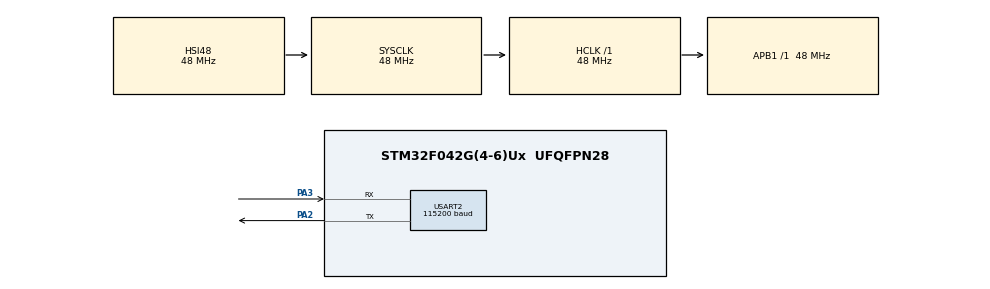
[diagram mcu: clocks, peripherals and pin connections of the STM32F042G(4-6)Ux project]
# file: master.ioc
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Mcu.Family=STM32F0
Mcu.Name=STM32F042G(4-6)Ux
Mcu.Package=UFQFPN28
NVIC.USART2_IRQn=true\:0\:0\:false\:false\:true\:true\:true
PA13.Mode=Serial_Wire
PA13.Signal=SYS_SWDIO
PA14.Mode=Serial_Wire
PA14.Signal=SYS_SWCLK
PA2.GPIO_PuPd=GPIO_PULLUP
PA2.Mode=Asynchronous
PA2.Signal=USART2_TX
PA3.GPIO_PuPd=GPIO_PULLUP
PA3.Mode=Asynchronous
PA3.Signal=USART2_RX
ProjectManager.HeapSize=0x200
ProjectManager.StackSize=0x400
ProjectManager.TargetToolchain=MDK-ARM V5
RCC.AHBFreq_Value=48000000
RCC.APB1Freq_Value=48000000
RCC.APB1TimFreq_Value=48000000
RCC.HCLKFreq_Value=48000000
RCC.SYSCLKFreq_VALUE=48000000
RCC.SYSCLKSource=RCC_SYSCLKSOURCE_HSI48
USART2.BaudRate=115200
USART2.VirtualMode-Asynchronous=VM_ASYNC
USART2.WordLength=WORDLENGTH_8B
board=master

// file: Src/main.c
/* USER CODE BEGIN Header */
/**
  ******************************************************************************
  * @file           : main.c
  * @brief          : Main program body
  ******************************************************************************
  * @attention
  *
  * <h2><center>&copy; Copyright (c) 2021 STMicroelectronics.
  * All rights reserved.</center></h2>
  *
  * This software component is licensed by ST under BSD 3-Clause license,
  * the "License"; You may not use this file except in compliance with the
  * License. You may obtain a copy of the License at:
  *                        opensource.org/licenses/BSD-3-Clause
  *
  ******************************************************************************
  */
/* USER CODE END Header */
#include "main.h"

/* USER CODE BEGIN Includes */
#include "modbus_master.h"
/* USER CODE END Includes */

UART_HandleTypeDef huart2;

/* USER CODE BEGIN PV */
/* Private variables ---------------------------------------------------------*/

/* USER CODE END PV */

void SystemClock_Config(void);
static void MX_GPIO_Init(void);
static void MX_USART2_UART_Init(void);
/* USER CODE BEGIN PFP */
/* Private function prototypes -----------------------------------------------*/

/* USER CODE END PFP */

int main(void)
{
  /* USER CODE BEGIN 1 */
  uint8_t state=0;
  uint16_t  Input_Result[2];
  /* USER CODE END 1 */

  /* MCU Configuration--------------------------------------------------------*/

  /* Reset of all peripherals, Initializes the Flash interface and the Systick. */
  HAL_Init();

  /* Configure the system clock */
  SystemClock_Config();

  /* Initialize all configured peripherals */
  MX_GPIO_Init();
  MX_USART2_UART_Init();
  /* USER CODE BEGIN 2 */
  ModbusMaster_begin();
  /* USER CODE END 2 */

  /* Infinite loop */
  /* USER CODE BEGIN WHILE */
  while (1)
  {
    uint8_t result;
    //测试Read Input Registers功能
    //从机地址0x01 ,寄存器地址 0x02 ,连续读2个寄存器地址
    result = ModbusMaster_readInputRegisters(0x01,0x2, 2);
    if (result == 0x00)
    {
      Input_Result[0] = ModbusMaster_getResponseBuffer(0x00);
      Input_Result[1] = ModbusMaster_getResponseBuffer(0x01);
    }
    HAL_Delay(1000);
    /* USER CODE END WHILE */

  }
}

void SystemClock_Config(void)
{
  RCC_OscInitTypeDef RCC_OscInitStruct = {0};
  RCC_ClkInitTypeDef RCC_ClkInitStruct = {0};

  /** Initializes the RCC Oscillators according to the specified parameters
  * in the RCC_OscInitTypeDef structure.
  */
  RCC_OscInitStruct.OscillatorType = RCC_OSCILLATORTYPE_HSI48;
  RCC_OscInitStruct.HSI48State = RCC_HSI48_ON;
  RCC_OscInitStruct.PLL.PLLState = RCC_PLL_NONE;
  if (HAL_RCC_OscConfig(&RCC_OscInitStruct) != HAL_OK)
  {
    Error_Handler();
  }
  /** Initializes the CPU, AHB and APB buses clocks
  */
  RCC_ClkInitStruct.ClockType = RCC_CLOCKTYPE_HCLK|RCC_CLOCKTYPE_SYSCLK
                              |RCC_CLOCKTYPE_PCLK1;
  RCC_ClkInitStruct.SYSCLKSource = RCC_SYSCLKSOURCE_HSI48;
  RCC_ClkInitStruct.AHBCLKDivider = RCC_SYSCLK_DIV1;
  RCC_ClkInitStruct.APB1CLKDivider = RCC_HCLK_DIV1;

  if (HAL_RCC_ClockConfig(&RCC_ClkInitStruct, FLASH_LATENCY_1) != HAL_OK)
  {
    Error_Handler();
  }
}

static void MX_USART2_UART_Init(void)
{

  huart2.Instance = USART2;
  huart2.Init.BaudRate = 115200;
  huart2.Init.WordLength = UART_WORDLENGTH_8B;
  huart2.Init.StopBits = UART_STOPBITS_1;
  huart2.Init.Parity = UART_PARITY_NONE;
  huart2.Init.Mode = UART_MODE_TX_RX;
  huart2.Init.HwFlowCtl = UART_HWCONTROL_NONE;
  huart2.Init.OverSampling = UART_OVERSAMPLING_16;
  huart2.Init.OneBitSampling = UART_ONE_BIT_SAMPLE_DISABLE;
  huart2.AdvancedInit.AdvFeatureInit = UART_ADVFEATURE_NO_INIT;
  if (HAL_UART_Init(&huart2) != HAL_OK)
  {
    Error_Handler();
  }

}

static void MX_GPIO_Init(void)
{

  /* GPIO Ports Clock Enable */
  __HAL_RCC_GPIOA_CLK_ENABLE();

}

void Error_Handler(void)
{
  while(1)
  {
  }
}

/************************ (C) COPYRIGHT STMicroelectronics *****END OF FILE****/
